# R7FA0E209 register map
Vendor: Renesas Electronics Corporation; Series: RA0; File version: 1.00.00
CPU: CM23 r1p0, little endian, no MPU, no FPU, VTOR, 2 interrupt priority bits, 64 interrupts
Registers are 16-bit, read-write, reset 0x0 unless marked. A register's access mark holds for its fields unless they carry their own. Offsets are from the block's base; [hi:lo] are bit positions; {n}, {i} and the like mark numbered series; 'fields as' and 'values as' point back to an identical list.

## UARTA — Serial Interface UARTA
Base 0x400A3400
{0x0+8i} TXBA{i} (i=0..1) 8-bit reset 0xFF — Transmit Buffer Register {i}
{0x1+8i} RXBA{i} (i=0..1) 8-bit ro reset 0xFF — Receive Buffer Register {i}
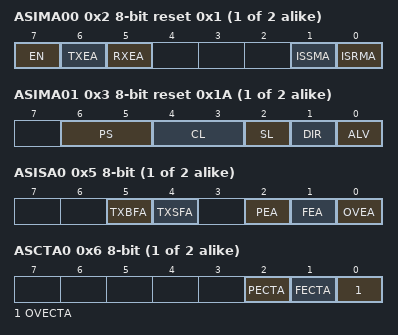
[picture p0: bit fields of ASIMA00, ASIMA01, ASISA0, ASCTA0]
{0x2+8i} ASIMA{i}0 (i=0..1) 8-bit reset 0x1 — Operation Mode Setting Register {i}0
  [7] EN — UART Operation Enable
    0=Disables the UART operation clock (resets the internal circuits); 1=Enables the UART operation clock
  [6] TXEA — Transmission Enable
    0=Disables transmission (resets the transmission circuit); 1=Enables transmission
  [5] RXEA — Reception Enable
    0=Disables reception (reset the reception circuit); 1=Enables reception
  [1] ISSMA — Transmit Interrupt Mode Select
    0=The UARTAn_TXI interrupt is generated on completion of transmission; 1=The UARTAn_TXI interrupt is generated when the transmit buffer becomes empty (for continuous transmission)
  [0] ISRMA — Receive Interrupt Mode Select
    0=The UARTAn_ERRI interrupt is generated when a reception error occurs (UARTAn_RXI is not generated); 1=The UARTAn_RXI interrupt is generated when a reception error occurs (UARTAn_ERRI is not generated)
{0x3+8i} ASIMA{i}1 (i=0..1) 8-bit reset 0x1A — Operation Mode Setting Register {i}1
  [6:5] PS — Transmission and Reception Parity Bit Setting
    0=Transmission: No parity bit is output. Reception: Data is received without parity.; 1=Transmission: 0 parity is output. Reception: Data is received with 0 parity.; 2=Transmission: Odd parity is output. Reception: Check is made for odd parity.; 3=Transmission: Even parity is output. Reception: Check is made for even parity.
  [4:3] CL — Transmission and Reception Character Length Setting
    0=Character length of data = 5 bits; 1=Setting prohibited; 2=Character length of data = 7 bits; 3=Character length of data = 8 bits
  [2] SL — Transmission Stop Bit Length Setting
    0=Stop bit length = 1 bit; 1=Stop bit length = 2 bits
  [1] DIR — Transmission and Reception Order Setting
    0=MSB first; 1=LSB first
  [0] ALV — Transmission and Reception Level Setting
    0=Positive logic (wait state = high level, start bit = low level, stop bit = high level); 1=Negative logic (wait state = low level, start bit = high level, stop bit = low level)
{0x4+8i} BRGCA{i} (i=0..1) 8-bit reset 0xFF — Baud Rate Generator Control Register {i}
{0x5+8i} ASISA{i} (i=0..1) 8-bit ro — Status Register {i}
  [5] TXBFA — Transmit Buffer Data Flag
    0=No valid data exists in the TXBAn register; 1=Valid data exists in the TXBAn register
  [4] TXSFA — Transmit Shift Register Data Flag
    0=Data is not being transmitted; 1=Data is being transmitted
  [2] PEA — Parity Error Flag
    0=No error has occurred; 1=An error has occurred
  [1] FEA — Framing Error Flag
    0=No error has occurred; 1=An error has occurred
  [0] OVEA — Overrun Error Flag
    0=No error has occurred; 1=An error has occurred
{0x6+8i} ASCTA{i} (i=0..1) 8-bit — Status Clear Trigger Register {i}
  [2] PECTA — Parity Error Flag Clear Trigger
    0=Does not clear the ASISAn.PEA flag (the flag is retained); 1=Clears the ASISAn.PEA flag
  [1] FECTA — Framing Error Flag Clear Trigger
    0=Does not clear the ASISAn.FEA flag (the flag is retained); 1=Clears the ASISAn.FEA flag
  [0] OVECTA — Overrun Error Flag Clear Trigger
    0=Does not clear the ASISAn.OVEA flag (the flag is retained); 1=Clears the ASISAn.OVEA flag
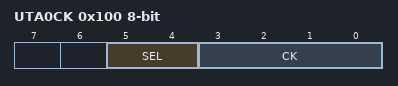
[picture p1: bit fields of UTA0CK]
0x100 UTA0CK 8-bit — UARTA Clock Select Register 0
  [5:4] SEL — fSEL Clock Select
    0=Stop; 1=MOSC; 2=HOCO; 3=MOCO
  [3:0] CK — UARTA0 Operation Clock Select (fUTA0)
    0=fSEL; 1=fSEL/2; 2=fSEL/4; 3=fSEL/8; 4=fSEL/16; 5=fSEL/32; 6=fSEL/64; 8=FSXP; other=Others (Setting prohibited)
0x101 UTA1CK 8-bit — UARTA Clock Select Register 1
  [3:0] CK — UARTA1 operation clock select (fUTA1)
    values as UTA0CK.CK
